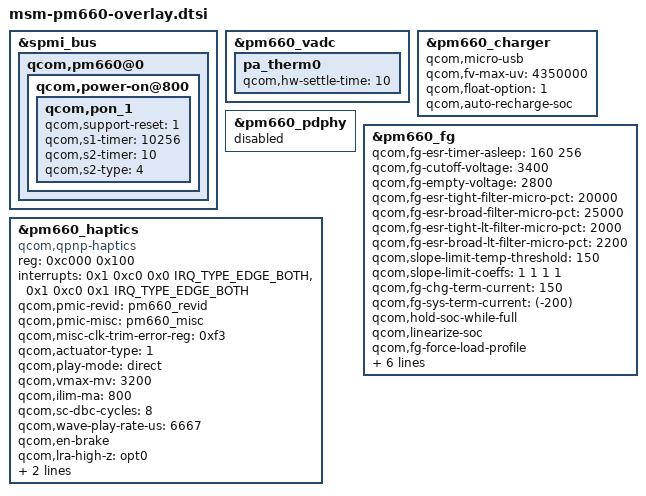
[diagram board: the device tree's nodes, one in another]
/* SPDX-License-Identifier: GPL-2.0 */

&spmi_bus {
	qcom,pm660@0 {
		qcom,power-on@800 {
			qcom,pon_1 {
				qcom,support-reset = <1>;
				qcom,s1-timer = <10256>;
				qcom,s2-timer = <10>;
				qcom,s2-type = <4>;
			};
		};
	};
};

&pm660_vadc {
	pa_therm0 {
		qcom,hw-settle-time = <10>; /* 10 ms */
	};
};

&pm660_charger {
	qcom,micro-usb;
	qcom,fv-max-uv = <4350000>;
	qcom,float-option = <1>;
	qcom,auto-recharge-soc;
};

&pm660_pdphy {
	status = "disabled";
};

&pm660_fg {
	qcom,fg-esr-timer-asleep = <160 256>;
	qcom,fg-cutoff-voltage = <3400>;
	qcom,fg-empty-voltage = <2800>;
	qcom,fg-esr-tight-filter-micro-pct = <20000>;
	qcom,fg-esr-broad-filter-micro-pct = <25000>;
	qcom,fg-esr-tight-lt-filter-micro-pct = <2000>;
	qcom,fg-esr-broad-lt-filter-micro-pct = <2200>;
	qcom,slope-limit-temp-threshold = <150>;
	qcom,slope-limit-coeffs = <1 1 1 1>;
	qcom,fg-chg-term-current = <150>;
	qcom,fg-sys-term-current = <(-200)>;
	qcom,hold-soc-while-full;
	qcom,linearize-soc;
	qcom,fg-force-load-profile;
	qcom,fg-jeita-thresholds = <0 1 59 60>;
	qcom,fg-jeita-hyst-temp = <3>;
	qcom,fg-recharge-voltage = <4150>;
	qcom,fg-recharge-soc-thr = <98>;
	qcom,fg-auto-recharge-soc;
	qcom,fg-rsense-sel=<1>;
};

&pm660_haptics {
        // leds-qpnp-vibrator  
	/*
	status = "okay";
	compatible = "qcom,qpnp-vibrator";
	reg = <0xc000 0x100>;
	label = "vibrator";
	qcom,vib-timeout-ms = <15000>;
	qcom,vib-vtg-level-mV = <3100>;
	qcom,mode = "manual"; */
	
	// led-qpnp-haptics
	compatible = "qcom,qpnp-haptics";
	reg = <0xc000 0x100>;
	interrupts = <0x1 0xc0 0x0 IRQ_TYPE_EDGE_BOTH>,
			<0x1 0xc0 0x1 IRQ_TYPE_EDGE_BOTH>;
	interrupt-names = "hap-sc-irq", "hap-play-irq";
	qcom,pmic-revid = <&pm660_revid>;
	qcom,pmic-misc = <&pm660_misc>;
	qcom,misc-clk-trim-error-reg = <0xf3>;
	qcom,actuator-type = <1>;
	qcom,play-mode = "direct";
	qcom,vmax-mv = <3200>;
	qcom,ilim-ma = <800>;
	qcom,sc-dbc-cycles = <8>;
	qcom,wave-play-rate-us = <6667>;
	qcom,en-brake;
	qcom,lra-high-z = "opt0";
	qcom,lra-auto-res-mode = "qwd";
	qcom,lra-res-cal-period = <4>;
};
